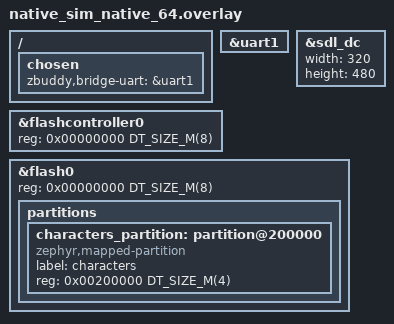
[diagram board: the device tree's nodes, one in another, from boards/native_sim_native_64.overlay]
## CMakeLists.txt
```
# Copyright (c) 2026 Muhammad Waleed Badar
# SPDX-License-Identifier: GPL-3.0-only

cmake_minimum_required(VERSION 3.20.0)

find_package(Zephyr REQUIRED HINTS $ENV{ZEPHYR_BASE})
project(zbuddy_app LANGUAGES C)

target_sources(app PRIVATE
  src/main.c
  src/buddy.c
  src/clock.c
  src/ui.c
  src/art_canvas.c
  src/character.c
  src/storage.c
  src/persist.c
  src/bridge.c
  src/hw.c
)

# The built-in character (tools/mkpack.py), shown until a pack is pushed
target_sources_ifdef(CONFIG_ZBUDDY_APP_BUILTIN_CHARACTER app PRIVATE src/builtin_pack.c)

# Transports: BLE (the desktop app) and a UART (tools/bridge_sim.py, tests)
target_sources_ifdef(CONFIG_BT app PRIVATE src/bridge_ble.c)
target_sources_ifdef(CONFIG_ZBUDDY_APP_UART_BRIDGE app PRIVATE src/bridge_uart.c)
# native_sim: command line options (screenshots, scripted bridge traffic)
target_sources_ifdef(CONFIG_BOARD_NATIVE_SIM app PRIVATE src/host.c)
```

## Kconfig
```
# Copyright (c) 2026 Muhammad Waleed Badar
# SPDX-License-Identifier: GPL-3.0-only

mainmenu "zbuddy"

DT_CHOSEN_BRIDGE_UART := zbuddy,bridge-uart

config ZBUDDY_APP_UART_BRIDGE
	bool "Speak the protocol over a UART as well (chosen zbuddy,bridge-uart)"
	default y if $(dt_chosen_enabled,$(DT_CHOSEN_BRIDGE_UART))
	depends on $(dt_chosen_enabled,$(DT_CHOSEN_BRIDGE_UART))
	select SERIAL
	select UART_INTERRUPT_DRIVEN
	help
	  The desktop app only talks BLE, but the same newline-delimited JSON
	  on a UART lets tools/bridge_sim.py drive the device, and is the
	  bridge of the native_sim build.

config ZBUDDY_APP_BUILTIN_CHARACTER
	bool "Built-in character pack (the clawd crab) until one is pushed"
	default y
	help
	  app/src/builtin_pack.c, generated by tools/mkpack.py from
	  characters/clawd. A pack pushed from the desktop replaces it; the
	  "delete char" reset brings it back.

config ZBUDDY_APP_BRIDGE_DEBUG
	bool "Log every write and notification of the bridge"
	help
	  Shows what the desktop sends and what the device answers, byte
	  counts and the first bytes of each line. Chatty during a pack push.

config ZBUDDY_APP_MOUNT_POINT
	string "Mount point of the character storage"
	default "/lfs"

config ZBUDDY_APP_SCREEN_OFF_S
	int "Turn the screen off after this many idle seconds (0 = never)"
	default 0
	help
	  The original device runs on a battery and sleeps after 30 s; a USB
	  powered board keeps the pet (and the clock) visible.

config ZBUDDY_APP_TICK_MS
	int "Animation tick of the ASCII pets (ms)"
	default 200

config ZBUDDY_APP_BLE_PREFIX
	string "Advertised name prefix (the desktop looks for Claude*)"
	default "Claude"

config ZBUDDY_APP_LED
	bool "Blink the RGB LED while an approval is pending"
	default y
	depends on LED_STRIP

config ZBUDDY_APP_SOUND
	bool "Beep on prompts and buttons (buzzer0 alias)"
	default y
	depends on BUZZER

source "Kconfig.zephyr"
```

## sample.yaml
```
# Copyright (c) 2026 Muhammad Waleed Badar
# SPDX-License-Identifier: GPL-3.0-only

sample:
  name: zbuddy
tests:
  app.zbuddy:
    build_only: true
    platform_allow:
      - native_sim/native/64
      - uedx32480035e_wb_a/esp32s3/procpu
    integration_platforms:
      - native_sim/native/64
    tags:
      - zbuddy
```

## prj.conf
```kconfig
# Copyright (c) 2026 Muhammad Waleed Badar
# SPDX-License-Identifier: GPL-3.0-only

# --- Buddy library -----------------------------------------------------------
CONFIG_ZBUDDY=y

# --- Kernel ------------------------------------------------------------------
# The main thread runs LVGL and the pet; it sleeps every iteration so that
# the Bluetooth, input, log and shell threads get the processor.
CONFIG_MAIN_THREAD_PRIORITY=12
CONFIG_MAIN_STACK_SIZE=16384
CONFIG_HEAP_MEM_POOL_SIZE=65536
CONFIG_LOG=y
CONFIG_LOG_DEFAULT_LEVEL=3
CONFIG_BASE64=y
CONFIG_REBOOT=y

# --- Character packs and settings on flash ----------------------------------
CONFIG_FLASH=y
CONFIG_FLASH_MAP=y
CONFIG_FILE_SYSTEM=y
CONFIG_FILE_SYSTEM_LITTLEFS=y
CONFIG_NVS=y
CONFIG_SETTINGS=y
CONFIG_SETTINGS_NVS=y

# --- Display and touch (LVGL) -------------------------------------------------
CONFIG_DISPLAY=y
CONFIG_INPUT=y
CONFIG_INPUT_QUEUE_MAX_MSGS=64
# The input thread runs the LVGL pointer callback, which logs when LVGL's
# queue is full; the default 1024 bytes overflowed on the ESP32-S3
CONFIG_INPUT_THREAD_STACK_SIZE=2048
CONFIG_LVGL=y
CONFIG_LV_Z_POINTER_INPUT=y
CONFIG_LV_Z_POINTER_INPUT_MSGQ_COUNT=64
CONFIG_LV_Z_MEM_POOL_SIZE=131072
CONFIG_LV_THEME_DEFAULT_DARK=y
CONFIG_LV_USE_LABEL=y
CONFIG_LV_USE_BUTTON=y
CONFIG_LV_USE_BAR=y
CONFIG_LV_USE_FLEX=y
CONFIG_LV_USE_CANVAS=y
CONFIG_LV_USE_GIF=y
CONFIG_LV_FONT_MONTSERRAT_12=y
CONFIG_LV_FONT_MONTSERRAT_14=y
CONFIG_LV_FONT_MONTSERRAT_16=y
CONFIG_LV_FONT_MONTSERRAT_20=y
CONFIG_LV_FONT_MONTSERRAT_28=y
CONFIG_LV_FONT_MONTSERRAT_48=y
CONFIG_LV_FONT_UNSCII_8=y
CONFIG_LV_FONT_UNSCII_16=y
CONFIG_LV_FONT_DEFAULT_MONTSERRAT_14=y
```

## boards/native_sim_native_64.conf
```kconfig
# Copyright (c) 2026 Muhammad Waleed Badar
# SPDX-License-Identifier: GPL-3.0-only
#
# native_sim/native/64: the SDL window stands in for the display, the mouse
# for the touch screen, a pseudo terminal (uart1) for the BLE link and the
# flash simulator (--flash=<file>) for the character storage and settings.

CONFIG_LV_COLOR_DEPTH_32=y
# The native backend prints the logs; the UART one would print them twice
CONFIG_LOG_BACKEND_UART=n

# Room for lv_snapshot_take() of the whole screen (--shot) and the GIFs
CONFIG_LV_USE_SNAPSHOT=y
CONFIG_LV_Z_MEM_POOL_SIZE=4194304

# Character packs are read into the kernel heap
CONFIG_HEAP_MEM_POOL_SIZE=16777216

# The console (logs) on the terminal; the bridge is uart1 on its own pty
CONFIG_UART_NATIVE_PTY_0_ON_STDINOUT=y
```

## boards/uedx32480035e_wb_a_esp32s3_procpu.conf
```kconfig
# Copyright (c) 2026 Muhammad Waleed Badar
# SPDX-License-Identifier: GPL-3.0-only
#
# VIEWE UEDX32480035E-WB-A (ESP32-S3): the BLE link to Claude Desktop, the
# character packs on the 16 MB flash, LVGL's pool and the GIFs in PSRAM.

CONFIG_ESP_SPIRAM=y
CONFIG_LV_Z_MEMORY_POOL_CUSTOM_SECTION=y
CONFIG_LV_Z_MEM_POOL_SIZE=524288
CONFIG_INPUT_THREAD_PRIORITY_OVERRIDE=y
CONFIG_INPUT_THREAD_PRIORITY=5
# Render the next strip while the previous one goes out over SPI
CONFIG_LV_Z_FLUSH_THREAD=y
CONFIG_LV_Z_DOUBLE_VDB=y

# --- Bluetooth LE: peripheral with the Nordic UART Service, LE Secure
# Connections with a passkey shown on the display, bonds in the settings
CONFIG_BT=y
CONFIG_BT_PERIPHERAL=y
CONFIG_BT_DEVICE_NAME="Claude"
CONFIG_BT_DEVICE_NAME_DYNAMIC=y
CONFIG_BT_SMP=y
CONFIG_BT_SMP_SC_PAIR_ONLY=y
CONFIG_BT_SETTINGS=y
CONFIG_BT_MAX_PAIRED=4
CONFIG_BT_L2CAP_TX_MTU=247
CONFIG_BT_BUF_ACL_RX_SIZE=251
CONFIG_BT_BUF_ACL_TX_SIZE=251
CONFIG_BT_GATT_CLIENT=n
# Show the desktop's traffic on the console while the link is being brought up
CONFIG_ZBUDDY_APP_BRIDGE_DEBUG=y

# --- The RGB LED blinks on a pending approval, the buzzer chirps
CONFIG_LED_STRIP=y
CONFIG_SPI=y
CONFIG_BUZZER=y
```

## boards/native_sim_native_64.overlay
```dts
/*
 * Copyright (c) 2026 Muhammad Waleed Badar
 * SPDX-License-Identifier: GPL-3.0-only
 *
 * The display has the geometry of the VIEWE board, upright like the device.
 * uart1 is the bridge: the simulator prints the pseudo terminal it is on,
 * tools/bridge_sim.py connects to it. The simulated flash grows to 8 MB to
 * hold a character pack next to the settings.
 */
/ {
	chosen {
		zbuddy,bridge-uart = &uart1;
	};
};

&uart1 {
	status = "okay";
};

&sdl_dc {
	width = <320>;
	height = <480>;
};

&flashcontroller0 {
	reg = <0x00000000 DT_SIZE_M(8)>;
};

&flash0 {
	reg = <0x00000000 DT_SIZE_M(8)>;
	ranges = <0x0 0x0 DT_SIZE_M(8)>;

	partitions {
		characters_partition: partition@200000 {
			compatible = "zephyr,mapped-partition";
			label = "characters";
			reg = <0x00200000 DT_SIZE_M(4)>;
		};
	};
};
```

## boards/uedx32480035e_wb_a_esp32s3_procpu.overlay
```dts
/*
 * Copyright (c) 2026 Muhammad Waleed Badar
 * SPDX-License-Identifier: GPL-3.0-only
 *
 * VIEWE UEDX32480035E-WB-A upright (320x480), the board's own orientation.
 * uart0 (the header pins) also speaks the protocol for tools/bridge_sim.py;
 * the console stays on the USB serial port.
 *
 * Flash: the application does not use MCUboot or the second core, so the
 * second image slots make room for a 4 MB character partition. The 192 KB
 * storage partition keeps the settings and the Bluetooth bonds.
 */
/ {
	chosen {
		zbuddy,bridge-uart = &uart0;
	};

	aliases {
		zbuddy-backlight = &{/lcd_backlight_en};
	};
};

/delete-node/ &slot1_partition;
/delete-node/ &slot0_appcpu_partition;
/delete-node/ &slot1_appcpu_partition;
/delete-node/ &slot0_lpcore_partition;
/delete-node/ &slot1_lpcore_partition;

&flash0 {
	partitions {
		characters_partition: partition@5f0000 {
			compatible = "zephyr,mapped-partition";
			label = "characters";
			reg = <0x5f0000 DT_SIZE_M(4)>;
		};
	};
};

/* GPIO0 is both the BOOT button and the RGB LED's data line (SPI3 MOSI).
 * Once the LED driver owns the pin it reads low, which the button driver
 * took for a press: a long press at boot opened the menu, and LED blinks
 * during a prompt could approve it. The LED wins; touch does the rest.
 */
&keys {
	status = "disabled";
};

/* Only the panel's gamma curves are set here */
&st7796s {
	pgc = [f0 06 0b 07 06 05 2e 33 47 3a 17 16 2e 31];
	ngc = [f0 09 0d 09 08 23 2e 33 46 38 13 13 2c 32];
};
```

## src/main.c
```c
/*
 * Copyright (c) 2026 Muhammad Waleed Badar
 * SPDX-License-Identifier: GPL-3.0-only
 *
 * zbuddy: a desk pet for Claude Desktop on Zephyr. It sleeps when nothing
 * is happening, wakes when sessions start, gets impatient when an approval
 * is pending, and lets you approve or deny from the device.
 */
#include "bridge.h"
#include "buddy.h"
#include "host.h"
#include "hw.h"
#include "persist.h"
#include "storage.h"
#include "ui.h"

#include <zbuddy/stats.h>
#include <zephyr/device.h>
#include <zephyr/drivers/display.h>
#include <zephyr/kernel.h>
#include <zephyr/logging/log.h>
#include <lvgl.h>

LOG_MODULE_REGISTER(zbuddy_app, LOG_LEVEL_INF);

int main(void)
{
	const struct device *display = DEVICE_DT_GET(DT_CHOSEN(zephyr_display));
	struct persist_data *d;
	uint32_t now = k_uptime_get_32();

	if (!device_is_ready(display)) {
		LOG_ERR("display not ready");
		return 0;
	}
	hw_init();
	persist_init();
	d = persist_get();
	zbuddy_stats_init(d->have_stats ? &d->stats : NULL, persist_save_stats, now);
	if (storage_init() != 0) {
		LOG_WRN("character storage unavailable");
	}
	ui_init();
	buddy_init(now);
	bridge_init();
	host_init();
	display_blanking_off(display);
	LOG_INF("zbuddy ready");

	for (;;) {
		struct hw_events ev;
		uint32_t next;

		now = k_uptime_get_32();
		bridge_poll(buddy_proto(), now);
		buddy_tick(now);
		hw_poll(now, &ev);
		if (ev.button_long) {
			buddy_long_press(now);
		} else if (ev.button_short) {
			buddy_button_short(now);
		}
		ui_update(now);
		host_poll(now);
		next = lv_timer_handler();
		/* at least a few ms: the lower-priority log and shell threads need it */
		k_msleep(CLAMP(next, 5, 20));
	}
	return 0;
}
```

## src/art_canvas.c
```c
/*
 * Copyright (c) 2026 Muhammad Waleed Badar
 * SPDX-License-Identifier: GPL-3.0-only
 */
#include "art_canvas.h"

#include <string.h>

LV_DRAW_BUF_DEFINE_STATIC(art_buf, ZBUDDY_ART_CANVAS_W, ZBUDDY_ART_CANVAS_H,
			  LV_COLOR_FORMAT_RGB565);

static lv_obj_t *canvas;
static lv_layer_t layer;
static lv_color_t cur_color;
static int cur_x, cur_y;

lv_color_t art_color_from_565(uint16_t c)
{
	uint8_t r = (uint8_t)(((c >> 11) & 0x1F) << 3);
	uint8_t g = (uint8_t)(((c >> 5) & 0x3F) << 2);
	uint8_t b = (uint8_t)((c & 0x1F) << 3);

	return lv_color_make((uint8_t)(r | (r >> 5)), (uint8_t)(g | (g >> 6)), (uint8_t)(b | (b >> 5)));
}

static void op_color(uint16_t rgb565)
{
	cur_color = art_color_from_565(rgb565);
}

static void op_cursor(int x, int y)
{
	cur_x = x;
	cur_y = y;
}

static void op_print(const char *s)
{
	lv_draw_label_dsc_t dsc;
	lv_area_t area;
	int len = (int)strlen(s);

	if (len == 0) {
		return;
	}
	lv_draw_label_dsc_init(&dsc);
	dsc.font = &lv_font_unscii_8;
	dsc.color = cur_color;
	dsc.text = s;
	dsc.text_local = 1;
	area.x1 = cur_x;
	area.y1 = cur_y;
	area.x2 = cur_x + len * ZBUDDY_ART_CHAR_W - 1;
	area.y2 = cur_y + ZBUDDY_ART_CHAR_H - 1;
	lv_draw_label(&layer, &dsc, &area);
	cur_x += len * ZBUDDY_ART_CHAR_W;
}

static const struct zbuddy_art_ops ops = {
	.set_color = op_color,
	.set_cursor = op_cursor,
	.print = op_print,
};

lv_obj_t *art_canvas_create(lv_obj_t *parent, int32_t scale)
{
	LV_DRAW_BUF_INIT_STATIC(art_buf);
	canvas = lv_canvas_create(parent);
	lv_canvas_set_draw_buf(canvas, &art_buf);
	lv_image_set_pivot(canvas, 0, 0);
	lv_image_set_scale(canvas, (uint32_t)LV_MAX(1, scale) * LV_SCALE_NONE);
	lv_image_set_antialias(canvas, false);
	lv_canvas_fill_bg(canvas, lv_color_black(), LV_OPA_COVER);
	zbuddy_art_bind(&ops);
	return canvas;
}

void art_canvas_render(const struct zbuddy_species *sp, enum zbuddy_persona s, uint32_t t,
		       uint16_t bg565)
{
	if (canvas == NULL) {
		return;
	}
	lv_canvas_fill_bg(canvas, art_color_from_565(bg565), LV_OPA_COVER);
	lv_canvas_init_layer(canvas, &layer);
	zbuddy_art_render(sp, s, t);
	lv_canvas_finish_layer(canvas, &layer);
	lv_obj_invalidate(canvas);
}
```

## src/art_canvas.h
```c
/*
 * Copyright (c) 2026 Muhammad Waleed Badar
 * SPDX-License-Identifier: GPL-3.0-only
 *
 * The text canvas of the ASCII species as an LVGL canvas: 160x88 at 1x,
 * shown at a whole pixel scale with nearest-neighbour scaling for the
 * pixel look.
 */
#ifndef ZBUDDY_APP_ART_CANVAS_H
#define ZBUDDY_APP_ART_CANVAS_H

#include <zbuddy/art.h>
#include <lvgl.h>

/** @p scale is the whole pixel scale the canvas is shown at. */
lv_obj_t *art_canvas_create(lv_obj_t *parent, int32_t scale);
/** Draw one frame; @p bg565 is the background colour. */
void art_canvas_render(const struct zbuddy_species *sp, enum zbuddy_persona s, uint32_t t,
		       uint16_t bg565);
lv_color_t art_color_from_565(uint16_t c);

#endif
```

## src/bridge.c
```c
/*
 * Copyright (c) 2026 Muhammad Waleed Badar
 * SPDX-License-Identifier: GPL-3.0-only
 */
#include "bridge.h"

#include <zephyr/kernel.h>
#include <zephyr/logging/log.h>
#include <zephyr/sys/ring_buffer.h>

#if defined(CONFIG_ZBUDDY_APP_BRIDGE_DEBUG)
LOG_MODULE_REGISTER(bridge, LOG_LEVEL_DBG);
#else
LOG_MODULE_REGISTER(bridge, LOG_LEVEL_INF);
#endif

RING_BUF_DECLARE(rx_ring, 8192);
static struct k_spinlock rx_lock;

void bridge_rx_put(const uint8_t *data, size_t len)
{
	k_spinlock_key_t key = k_spin_lock(&rx_lock);
	uint32_t n = ring_buf_put(&rx_ring, data, (uint32_t)len);

	k_spin_unlock(&rx_lock, key);
	if (n < len) {
		LOG_WRN("rx ring full, %u bytes dropped", (unsigned int)(len - n));
	}
}

void bridge_poll(struct zbuddy_proto *p, uint32_t now_ms)
{
	uint8_t buf[256];

#if defined(CONFIG_BT)
	bridge_ble_poll(now_ms);
#endif
	for (;;) {
		k_spinlock_key_t key = k_spin_lock(&rx_lock);
		uint32_t n = ring_buf_get(&rx_ring, buf, sizeof(buf));

		k_spin_unlock(&rx_lock, key);
		if (n == 0) {
			return;
		}
		LOG_DBG("feeding %u bytes", n);
		zbuddy_proto_feed(p, buf, n, now_ms);
	}
}

void bridge_send(const char *line, size_t len)
{
#if defined(CONFIG_BT)
	bridge_ble_send(line, len);
#endif
#if defined(CONFIG_ZBUDDY_APP_UART_BRIDGE)
	bridge_uart_send(line, len);
#endif
}

void bridge_init(void)
{
#if defined(CONFIG_ZBUDDY_APP_UART_BRIDGE)
	if (bridge_uart_init() != 0) {
		LOG_WRN("uart bridge unavailable");
	}
#endif
#if defined(CONFIG_BT)
	if (bridge_ble_init() != 0) {
		LOG_WRN("bluetooth unavailable");
	}
#endif
}

static uint32_t debug_passkey;

void bridge_debug_passkey(uint32_t passkey)
{
	debug_passkey = passkey;
}

uint32_t bridge_debug_passkey_get(void)
{
	return debug_passkey;
}

#if !defined(CONFIG_BT)
bool bridge_ble_available(void)
{
	return false;
}
bool bridge_ble_connected(void)
{
	return false;
}
bool bridge_ble_secure(void)
{
	return false;
}
uint32_t bridge_ble_passkey(void)
{
	return debug_passkey;
}
const char *bridge_ble_name(void)
{
	return "(no bluetooth)";
}
const char *bridge_ble_addr(void)
{
	return "-";
}
void bridge_ble_unpair(void)
{
}
#endif
```

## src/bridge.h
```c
/*
 * Copyright (c) 2026 Muhammad Waleed Badar
 * SPDX-License-Identifier: GPL-3.0-only
 *
 * The bridge: bytes between the desktop and the protocol parser, over BLE
 * (Nordic UART Service) and optionally a UART. Both transports push into
 * one receive ring; the main loop drains it into the parser. Lines sent by
 * the parser go to every transport that is up.
 */
#ifndef ZBUDDY_APP_BRIDGE_H
#define ZBUDDY_APP_BRIDGE_H

#include <zbuddy/proto.h>

void bridge_init(void);
/** Drain received bytes into the parser. */
void bridge_poll(struct zbuddy_proto *p, uint32_t now_ms);
/** Send one line to all transports. */
void bridge_send(const char *line, size_t len);
/** Transports call this from any context. */
void bridge_rx_put(const uint8_t *data, size_t len);

/* Bluetooth facts for the screens; stubs without CONFIG_BT */
bool bridge_ble_available(void);
bool bridge_ble_connected(void);
bool bridge_ble_secure(void);
/** Non-zero while a passkey must be shown to the user. */
uint32_t bridge_ble_passkey(void);
const char *bridge_ble_name(void);
const char *bridge_ble_addr(void);
void bridge_ble_unpair(void);

/* Implemented by the transports */
int bridge_ble_init(void);
void bridge_ble_send(const char *line, size_t len);
/** Keeps advertising alive while disconnected; call every loop. */
void bridge_ble_poll(uint32_t now_ms);
int bridge_uart_init(void);
void bridge_uart_send(const char *line, size_t len);

/** Debug: pretend a passkey is being shown (screenshots). */
void bridge_debug_passkey(uint32_t passkey);
uint32_t bridge_debug_passkey_get(void);

#endif
```

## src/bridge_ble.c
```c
/*
 * Copyright (c) 2026 Muhammad Waleed Badar
 * SPDX-License-Identifier: GPL-3.0-only
 *
 * BLE peripheral for Claude Desktop: the Nordic UART Service UUIDs with
 * encrypted-only characteristics, LE Secure Connections bonding with the
 * passkey shown on the display (DisplayOnly), advertised as "Claude-XXXX".
 */
#include "bridge.h"

#include <stdio.h>
#include <string.h>
#include <zephyr/bluetooth/bluetooth.h>
#include <zephyr/bluetooth/conn.h>
#include <zephyr/bluetooth/gatt.h>
#include <zephyr/bluetooth/hci.h>
#include <zephyr/bluetooth/uuid.h>
#include <zephyr/kernel.h>
#include <zephyr/logging/log.h>
#include <zephyr/settings/settings.h>

#if defined(CONFIG_ZBUDDY_APP_BRIDGE_DEBUG)
LOG_MODULE_REGISTER(bridge_ble, LOG_LEVEL_DBG);
#else
LOG_MODULE_REGISTER(bridge_ble, LOG_LEVEL_INF);
#endif

#define NUS_SRV_VAL BT_UUID_128_ENCODE(0x6e400001, 0xb5a3, 0xf393, 0xe0a9, 0xe50e24dcca9e)
#define NUS_RX_VAL BT_UUID_128_ENCODE(0x6e400002, 0xb5a3, 0xf393, 0xe0a9, 0xe50e24dcca9e)
#define NUS_TX_VAL BT_UUID_128_ENCODE(0x6e400003, 0xb5a3, 0xf393, 0xe0a9, 0xe50e24dcca9e)

static struct bt_conn *current;
static bool notify_enabled;
static bool secure;
static uint32_t passkey;
static char dev_name[24] = CONFIG_ZBUDDY_APP_BLE_PREFIX;
static char dev_addr[BT_ADDR_LE_STR_LEN] = "-";

static ssize_t rx_write(struct bt_conn *conn, const struct bt_gatt_attr *attr, const void *buf,
			uint16_t len, uint16_t offset, uint8_t flags)
{
	ARG_UNUSED(conn);
	ARG_UNUSED(attr);
	ARG_UNUSED(offset);
	ARG_UNUSED(flags);
	LOG_DBG("rx %u bytes: %.*s", len, (int)MIN(len, 60), (const char *)buf);
	bridge_rx_put(buf, len);
	return len;
}

static void tx_ccc_changed(const struct bt_gatt_attr *attr, uint16_t value)
{
	ARG_UNUSED(attr);
	notify_enabled = (value == BT_GATT_CCC_NOTIFY);
	LOG_INF("notifications %s", notify_enabled ? "on" : "off");
}

BT_GATT_SERVICE_DEFINE(nus_svc, BT_GATT_PRIMARY_SERVICE(BT_UUID_DECLARE_128(NUS_SRV_VAL)),
		       BT_GATT_CHARACTERISTIC(BT_UUID_DECLARE_128(NUS_TX_VAL), BT_GATT_CHRC_NOTIFY,
					      BT_GATT_PERM_READ_ENCRYPT, NULL, NULL, NULL),
		       BT_GATT_CCC(tx_ccc_changed,
				   BT_GATT_PERM_READ_ENCRYPT | BT_GATT_PERM_WRITE_ENCRYPT),
		       BT_GATT_CHARACTERISTIC(BT_UUID_DECLARE_128(NUS_RX_VAL),
					      BT_GATT_CHRC_WRITE | BT_GATT_CHRC_WRITE_WITHOUT_RESP,
					      BT_GATT_PERM_WRITE_ENCRYPT, NULL, rx_write, NULL), );

#define TX_ATTR (&nus_svc.attrs[2])

static const struct bt_data ad[] = {
	BT_DATA_BYTES(BT_DATA_FLAGS, (BT_LE_AD_GENERAL | BT_LE_AD_NO_BREDR)),
	BT_DATA(BT_DATA_NAME_COMPLETE, dev_name, 0), /* length patched at start */
};

static const struct bt_data sd[] = {
	BT_DATA_BYTES(BT_DATA_UUID128_ALL, NUS_SRV_VAL),
};

static bool advertising;

static void start_adv(void)
{
	struct bt_data ad_now[2] = {ad[0], ad[1]};
	int err;

	ad_now[1].data_len = (uint8_t)strlen(dev_name);
	err = bt_le_adv_start(BT_LE_ADV_CONN_FAST_1, ad_now, ARRAY_SIZE(ad_now), sd, ARRAY_SIZE(sd));
	if (err == -EALREADY) {
		advertising = true;
	} else if (err != 0) {
		advertising = false;
		LOG_ERR("advertising failed (%d)", err);
	} else {
		advertising = true;
		LOG_INF("advertising as '%s'", dev_name);
	}
}

/* Advertising must be running whenever nobody is connected: a failed
 * pairing followed by a disconnect from both sides can leave it stopped,
 * so the main loop checks it every few seconds.
 */
void bridge_ble_poll(uint32_t now_ms)
{
	static uint32_t next_check;

	if ((int32_t)(now_ms - next_check) < 0) {
		return;
	}
	next_check = now_ms + 5000;
	if (current == NULL && !advertising) {
		LOG_WRN("advertising stopped, restarting");
		start_adv();
	}
}

static void connected(struct bt_conn *conn, uint8_t err)
{
	advertising = false; /* a connectable advertiser stops on connection */
	if (err != 0) {
		LOG_WRN("connection failed (%u)", err);
		start_adv();
		return;
	}
	current = bt_conn_ref(conn);
	secure = false;
	passkey = 0;
	{
		char addr[BT_ADDR_LE_STR_LEN];

		bt_addr_le_to_str(bt_conn_get_dst(conn), addr, sizeof(addr));
		LOG_INF("connected to %s", addr);
	}
}

static void disconnected(struct bt_conn *conn, uint8_t reason)
{
	LOG_INF("disconnected (%u)", reason);
	if (current == conn) {
		bt_conn_unref(current);
		current = NULL;
	}
	notify_enabled = false;
	secure = false;
	passkey = 0;
}

static void recycled(void)
{
	start_adv();
}

static void security_changed(struct bt_conn *conn, bt_security_t level, enum bt_security_err err)
{
	ARG_UNUSED(conn);
	secure = (err == BT_SECURITY_ERR_SUCCESS && level >= BT_SECURITY_L2);
	LOG_INF("security level %d (%d), mtu %u", level, err, bt_gatt_get_mtu(conn));
}

static void le_param_updated(struct bt_conn *conn, uint16_t interval, uint16_t latency,
			     uint16_t timeout)
{
	ARG_UNUSED(conn);
	LOG_INF("conn params: interval %u.%02u ms, latency %u, timeout %u ms", interval * 125 / 100,
		(interval * 125) % 100, latency, timeout * 10);
}

BT_CONN_CB_DEFINE(conn_cbs) = {
	.connected = connected,
	.disconnected = disconnected,
	.recycled = recycled,
	.security_changed = security_changed,
	.le_param_updated = le_param_updated,
};

static void passkey_display(struct bt_conn *conn, unsigned int key)
{
	ARG_UNUSED(conn);
	passkey = key;
	LOG_INF("passkey %06u", key);
}

static void auth_cancel(struct bt_conn *conn)
{
	ARG_UNUSED(conn);
	passkey = 0;
	LOG_INF("pairing cancelled");
}

static const struct bt_conn_auth_cb auth_cb = {
	.passkey_display = passkey_display,
	.cancel = auth_cancel,
};

static void pairing_complete(struct bt_conn *conn, bool bonded)
{
	ARG_UNUSED(conn);
	passkey = 0;
	LOG_INF("pairing complete, %s", bonded ? "bonded" : "not bonded");
}

static void pairing_failed(struct bt_conn *conn, enum bt_security_err reason)
{
	passkey = 0;
	LOG_WRN("pairing failed (%d): %s", reason,
		reason == BT_SECURITY_ERR_AUTH_REQUIREMENT
			? "the host offers no passkey entry (pair it with an agent)"
		: reason == BT_SECURITY_ERR_PIN_OR_KEY_MISSING
			? "stale bond on the host, pair again"
			: "");
	bt_conn_disconnect(conn, BT_HCI_ERR_AUTH_FAIL);
}

static struct bt_conn_auth_info_cb auth_info_cb = {
	.pairing_complete = pairing_complete,
	.pairing_failed = pairing_failed,
};

int bridge_ble_init(void)
{
	bt_addr_le_t addrs[CONFIG_BT_ID_MAX];
	size_t count = ARRAY_SIZE(addrs);
	int err;

	err = bt_enable(NULL);
	if (err != 0) {
		LOG_ERR("bt_enable failed (%d)", err);
		return err;
	}
	if (IS_ENABLED(CONFIG_BT_SETTINGS)) {
		settings_load_subtree("bt");
	}
	bt_conn_auth_cb_register(&auth_cb);
	bt_conn_auth_info_cb_register(&auth_info_cb);

	/* "Claude-XXXX" with the last two bytes of the address, so several
	 * buddies in one room are distinguishable in the desktop picker.
	 */
	bt_id_get(addrs, &count);
	if (count > 0) {
		snprintf(dev_name, sizeof(dev_name), "%s-%02X%02X", CONFIG_ZBUDDY_APP_BLE_PREFIX,
			 addrs[0].a.val[1], addrs[0].a.val[0]);
		bt_addr_le_to_str(&addrs[0], dev_addr, sizeof(dev_addr));
		dev_addr[17] = '\0'; /* drop the " (public)" suffix */
	}
	bt_set_name(dev_name);
	start_adv();
	return 0;
}

void bridge_ble_send(const char *line, size_t len)
{
	size_t sent = 0;

	if (current == NULL || !notify_enabled) {
		return;
	}
	while (sent < len) {
		uint16_t mtu = bt_gatt_get_mtu(current);
		size_t chunk = mtu > 3 ? mtu - 3 : 20;
		size_t n = len - sent;
		int err;

		if (chunk > 244) {
			chunk = 244;
		}
		if (n > chunk) {
			n = chunk;
		}
		LOG_DBG("tx %u bytes: %.*s", (unsigned int)n, (int)MIN(n, 60), line + sent);
		err = bt_gatt_notify(current, TX_ATTR, line + sent, (uint16_t)n);
		if (err == -ENOMEM || err == -EAGAIN) {
			k_msleep(4);
			continue;
		}
		if (err != 0) {
			LOG_WRN("notify failed (%d)", err);
			return;
		}
		sent += n;
	}
}

bool bridge_ble_available(void)
{
	return true;
}

bool bridge_ble_connected(void)
{
	return current != NULL;
}

bool bridge_ble_secure(void)
{
	return secure;
}

uint32_t bridge_ble_passkey(void)
{
	return passkey != 0 ? passkey : bridge_debug_passkey_get();
}

const char *bridge_ble_name(void)
{
	return dev_name;
}

const char *bridge_ble_addr(void)
{
	return dev_addr;
}

void bridge_ble_unpair(void)
{
	int err = bt_unpair(BT_ID_DEFAULT, BT_ADDR_LE_ANY);

	LOG_INF("bonds cleared (%d)", err);
}
```

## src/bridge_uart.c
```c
/*
 * Copyright (c) 2026 Muhammad Waleed Badar
 * SPDX-License-Identifier: GPL-3.0-only
 *
 * The protocol over the chosen zbuddy,bridge-uart: interrupt driven
 * receive into the bridge ring, polled transmit (lines are short).
 */
#include "bridge.h"

#include <zephyr/device.h>
#include <zephyr/drivers/uart.h>
#include <zephyr/kernel.h>
#include <zephyr/logging/log.h>

LOG_MODULE_REGISTER(bridge_uart, LOG_LEVEL_INF);

static const struct device *const uart = DEVICE_DT_GET(DT_CHOSEN(zbuddy_bridge_uart));
static bool ready;

static void uart_isr(const struct device *dev, void *user_data)
{
	uint8_t buf[64];

	ARG_UNUSED(user_data);
	uart_irq_update(dev);
	while (uart_irq_rx_ready(dev)) {
		int n = uart_fifo_read(dev, buf, sizeof(buf));

		if (n <= 0) {
			break;
		}
		bridge_rx_put(buf, (size_t)n);
	}
}

int bridge_uart_init(void)
{
	if (!device_is_ready(uart)) {
		return -ENODEV;
	}
	uart_irq_callback_user_data_set(uart, uart_isr, NULL);
	uart_irq_rx_enable(uart);
	ready = true;
	LOG_INF("bridge on %s", uart->name);
	return 0;
}

void bridge_uart_send(const char *line, size_t len)
{
	if (!ready) {
		return;
	}
	for (size_t i = 0; i < len; i++) {
		uart_poll_out(uart, (unsigned char)line[i]);
	}
}
```

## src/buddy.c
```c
/*
 * Copyright (c) 2026 Muhammad Waleed Badar
 * SPDX-License-Identifier: GPL-3.0-only
 */
#include "buddy.h"
#include "bridge.h"
#include "character.h"
#include "clock.h"
#include "hw.h"
#include "storage.h"

#include <stdio.h>
#include <string.h>
#include <zbuddy/art.h>
#include <zbuddy/stats.h>
#include <zephyr/kernel.h>
#include <zephyr/logging/log.h>
#include <zephyr/sys/reboot.h>

LOG_MODULE_REGISTER(buddy, LOG_LEVEL_INF);

#define SPECIES_GIF 0xFF
#define WAKE_TRANSITION_MS 12000
#define RESET_CONFIRM_MS 3000

static struct buddy_model m;
static struct zbuddy_proto proto;
static char last_prompt_id[sizeof(((struct zbuddy_prompt *)0)->id)];
static int forced_persona = -1;

static const char *const menu_items[] = {"settings", "nap", "help", "about", "demo", "close"};
static const char *const settings_items[] = {"sound", "led", "transcript", "ascii pet",
					     "reset", "back"};
static const char *const reset_items[] = {"delete char", "factory reset", "back"};

/* --- protocol callbacks ---------------------------------------------------- */

static void op_send(const char *line, size_t len)
{
	bridge_send(line, len);
}

static void op_set_name(const char *name)
{
	struct persist_data *d = persist_get();

	strncpy(d->name, name, sizeof(d->name) - 1);
	d->name[sizeof(d->name) - 1] = '\0';
	persist_save_name();
}

static const char *op_get_name(void)
{
	return persist_get()->name;
}

static void op_set_owner(const char *name)
{
	struct persist_data *d = persist_get();

	strncpy(d->owner, name, sizeof(d->owner) - 1);
	d->owner[sizeof(d->owner) - 1] = '\0';
	persist_save_owner();
}

static const char *op_get_owner(void)
{
	return persist_get()->owner;
}

static void op_time_sync(int64_t epoch_s, int32_t tz_offset_s)
{
	clock_sync(epoch_s, tz_offset_s, k_uptime_get_32());
}

static void op_sys_info(struct zbuddy_sys_info *info)
{
	info->uptime_s = k_uptime_get_32() / 1000U;
	storage_space(&info->fs_free, &info->fs_total);
}

static const struct zbuddy_proto_ops ops = {
	.send = op_send,
	.set_name = op_set_name,
	.get_name = op_get_name,
	.set_owner = op_set_owner,
	.get_owner = op_get_owner,
	.set_species = buddy_set_species,
	.unpair = bridge_ble_unpair,
	.time_sync = op_time_sync,
	.sys_info = op_sys_info,
	.secure = bridge_ble_secure,
	/* .store is set at init: the storage may be absent */
};

static struct zbuddy_proto_ops live_ops;

/* --- helpers ----------------------------------------------------------------- */

static void beep(uint32_t ms)
{
	if (persist_get()->prefs.sound) {
		hw_beep(ms);
	}
}

static void one_shot(enum zbuddy_persona s, uint32_t dur_ms, uint32_t now_ms)
{
	m.active = s;
	m.one_shot_until = now_ms + dur_ms;
	m.anim_gen++;
}

void buddy_wake(uint32_t now_ms)
{
	m.last_interact_ms = now_ms;
	if (m.napping) {
		m.napping = false;
		zbuddy_stats_on_nap_end((now_ms - m.nap_start_ms) / 1000U, now_ms);
	}
	if (m.screen_off) {
		m.screen_off = false;
		hw_screen(true);
		m.wake_transition_until = now_ms + WAKE_TRANSITION_MS;
		m.anim_gen++;
	}
}

static void close_overlays(void)
{
	m.overlay = OVERLAY_NONE;
	m.sel = 0;
	m.reset_armed = 0xFF;
}

static void next_pet(void)
{
	struct persist_data *d = persist_get();
	uint8_t n = (uint8_t)zbuddy_species_count();

	if (!m.ascii_mode) { /* pack -> first species */
		m.ascii_mode = true;
		m.species_idx = 0;
	} else if (m.species_idx + 1 >= n && m.gif_available) { /* last species -> pack */
		m.ascii_mode = false;
	} else {
		m.species_idx = (uint8_t)((m.species_idx + 1) % n);
	}
	d->species = m.ascii_mode ? m.species_idx : SPECIES_GIF;
	persist_save_species();
	m.anim_gen++;
}

void buddy_set_species(uint8_t idx)
{
	struct persist_data *d = persist_get();

	m.gif_available = character_loaded();
	d->species = idx;
	persist_save_species();
	m.ascii_mode = !(m.gif_available && idx == SPECIES_GIF);
	if (m.ascii_mode && idx < zbuddy_species_count()) {
		m.species_idx = idx;
	}
	m.anim_gen++;
}

const char *buddy_species_name(void)
{
	if (m.ascii_mode) {
		const struct zbuddy_species *sp = zbuddy_species_get(m.species_idx);

		return sp != NULL ? sp->name : "?";
	}
	return character_loaded() ? character_name() : "none";
}

/* --- menus ------------------------------------------------------------------- */

static void apply_setting(uint8_t idx, uint32_t now_ms)
{
	struct persist_data *d = persist_get();

	ARG_UNUSED(now_ms);
	switch (idx) {
	case 0:
		d->prefs.sound = !d->prefs.sound;
		break;
	case 1:
		d->prefs.led = !d->prefs.led;
		if (!d->prefs.led) {
			hw_led(false);
		}
		break;
	case 2:
		d->prefs.hud = !d->prefs.hud;
		break;
	case 3:
		next_pet();
		return;
	case 4:
		m.overlay = OVERLAY_RESET;
		m.sel = 0;
		m.reset_armed = 0xFF;
		return;
	default:
		close_overlays();
		return;
	}
	persist_save_prefs();
}

/* Tap-twice confirm: the first activation arms ("really?"), the second
 * within three seconds executes.
 */
static void apply_reset(uint8_t idx, uint32_t now_ms)
{
	bool armed = (m.reset_armed == idx) && (int32_t)(now_ms - m.reset_armed_until) < 0;

	if (idx == 2) {
		close_overlays();
		return;
	}
	if (!armed) {
		m.reset_armed = idx;
		m.reset_armed_until = now_ms + RESET_CONFIRM_MS;
		beep(60);
		return;
	}
	beep(200);
	if (idx == 0) {
		character_close();
		storage_wipe_characters();
		character_init(NULL); /* the built-in pack, when there is one */
		m.gif_available = character_loaded();
		m.ascii_mode = !m.gif_available;
		persist_get()->species = m.ascii_mode ? m.species_idx : SPECIES_GIF;
		persist_save_species();
		close_overlays();
		m.anim_gen++;
		return;
	}
	/* factory reset: names, stats, preferences, packs and bonds */
	character_close();
	storage_wipe_characters();
	persist_wipe();
	zbuddy_stats_reset(now_ms);
	bridge_ble_unpair();
	k_msleep(300);
	sys_reboot(SYS_REBOOT_COLD);
}

static void menu_confirm(uint8_t idx, uint32_t now_ms)
{
	switch (idx) {
	case 0:
		m.overlay = OVERLAY_SETTINGS;
		m.sel = 0;
		break;
	case 1: /* nap: the screen goes dark until the next touch */
		close_overlays();
		m.napping = true;
		m.nap_start_ms = now_ms;
		m.screen_off = true;
		hw_screen(false);
		break;
	case 2:
	case 3:
		close_overlays();
		m.screen = SCREEN_INFO;
		m.info_page = (idx == 2) ? INFO_PG_BUTTONS : INFO_PG_CREDITS;
		break;
	case 4:
		zbuddy_proto_set_demo(&proto, !zbuddy_proto_demo(&proto), now_ms);
		break;
	default:
		close_overlays();
		break;
	}
}

void buddy_pick(uint8_t idx, uint32_t now_ms)
{
	buddy_wake(now_ms);
	beep(30);
	m.sel = idx;
	switch (m.overlay) {
	case OVERLAY_MENU:
		menu_confirm(idx, now_ms);
		break;
	case OVERLAY_SETTINGS:
		apply_setting(idx, now_ms);
		break;
	case OVERLAY_RESET:
		apply_reset(idx, now_ms);
		break;
	default:
		break;
	}
}

const char *buddy_overlay_title(void)
{
	switch (m.overlay) {
	case OVERLAY_MENU:
		return "menu";
	case OVERLAY_SETTINGS:
		return "settings";
	case OVERLAY_RESET:
		return "reset";
	default:
		return "";
	}
}

uint8_t buddy_overlay_items(void)
{
	switch (m.overlay) {
	case OVERLAY_MENU:
		return ARRAY_SIZE(menu_items);
	case OVERLAY_SETTINGS:
		return ARRAY_SIZE(settings_items);
	case OVERLAY_RESET:
		return ARRAY_SIZE(reset_items);
	default:
		return 0;
	}
}

void buddy_overlay_item(uint8_t idx, char *buf, size_t len, uint32_t now_ms)
{
	const struct buddy_prefs *p = &persist_get()->prefs;

	switch (m.overlay) {
	case OVERLAY_MENU:
		if (idx == 4) {
			snprintf(buf, len, "%-12s%s", menu_items[idx],
				 zbuddy_proto_demo(&proto) ? "on" : "off");
		} else {
			snprintf(buf, len, "%s", menu_items[idx]);
		}
		break;
	case OVERLAY_SETTINGS:
		switch (idx) {
		case 0:
		case 1:
		case 2: {
			bool v = idx == 0 ? p->sound : idx == 1 ? p->led : p->hud;

			snprintf(buf, len, "%-12s%s", settings_items[idx], v ? "on" : "off");
			break;
		}
		case 3: {
			uint8_t total = (uint8_t)zbuddy_species_count() + (m.gif_available ? 1 : 0);
			uint8_t pos = m.ascii_mode ? m.species_idx + 1 : total;

			snprintf(buf, len, "%-12s%u/%u %s", settings_items[idx], pos, total,
				 buddy_species_name());
			break;
		}
		default:
			snprintf(buf, len, "%s", settings_items[idx]);
			break;
		}
		break;
	case OVERLAY_RESET: {
		bool armed = (m.reset_armed == idx) && (int32_t)(now_ms - m.reset_armed_until) < 0;

		snprintf(buf, len, "%s", armed ? "really?" : reset_items[idx]);
		break;
	}
	default:
		buf[0] = '\0';
		break;
	}
}

/* --- inputs ------------------------------------------------------------------ */

static void send_decision(bool approve, uint32_t now_ms)
{
	const struct zbuddy_snapshot *s = &proto.snap;

	if (!m.in_prompt) {
		return;
	}
	zbuddy_proto_permission(&proto, s->prompt.id, approve);
	LOG_INF("prompt %s: %s", s->prompt.id, approve ? "approved" : "denied");
	m.response_sent = true;
	m.in_prompt = false;
	if (approve) {
		uint32_t took_s = (now_ms - m.prompt_arrived_ms) / 1000U;

		zbuddy_stats_on_approval(took_s);
		beep(60);
		if (took_s < 5) {
			one_shot(ZBUDDY_HEART, 2000, now_ms);
		}
	} else {
		zbuddy_stats_on_denial();
		beep(60);
	}
}

void buddy_approve(uint32_t now_ms)
{
	buddy_wake(now_ms);
	send_decision(true, now_ms);
}

void buddy_deny(uint32_t now_ms)
{
	buddy_wake(now_ms);
	send_decision(false, now_ms);
}

void buddy_tap_pet(uint32_t now_ms)
{
	bool was_off = m.screen_off;

	buddy_wake(now_ms);
	if (was_off || m.overlay != OVERLAY_NONE) {
		return;
	}
	if (m.in_prompt) {
		send_decision(true, now_ms);
		return;
	}
	beep(30);
	m.screen = (enum buddy_screen)((m.screen + 1) % SCREEN_COUNT);
}

void buddy_next_page(uint32_t now_ms)
{
	bool was_off = m.screen_off;

	buddy_wake(now_ms);
	if (was_off || m.overlay != OVERLAY_NONE) {
		return;
	}
	beep(30);
	if (m.screen == SCREEN_INFO) {
		m.info_page = (uint8_t)((m.info_page + 1) % INFO_PAGES);
	} else if (m.screen == SCREEN_PET) {
		m.pet_page = (uint8_t)((m.pet_page + 1) % PET_PAGES);
	}
}

void buddy_long_press(uint32_t now_ms)
{
	bool was_off = m.screen_off;

	buddy_wake(now_ms);
	if (was_off) {
		return;
	}
	beep(60);
	if (m.overlay != OVERLAY_NONE) {
		buddy_pick(m.sel, now_ms);
		return;
	}
	m.overlay = OVERLAY_MENU;
	m.sel = 0;
}

void buddy_button_short(uint32_t now_ms)
{
	bool was_off = m.screen_off;

	buddy_wake(now_ms);
	if (was_off) {
		return;
	}
	if (m.overlay != OVERLAY_NONE) {
		beep(30);
		m.sel = (uint8_t)((m.sel + 1) % buddy_overlay_items());
		if (m.overlay == OVERLAY_RESET) {
			m.reset_armed = 0xFF;
		}
		return;
	}
	buddy_tap_pet(now_ms);
}

void buddy_shake(uint32_t now_ms)
{
	if (m.overlay != OVERLAY_NONE || m.screen_off) {
		return;
	}
	buddy_wake(now_ms);
	if ((int32_t)(now_ms - m.one_shot_until) >= 0) {
		one_shot(ZBUDDY_DIZZY, 2000, now_ms);
		LOG_INF("shake: dizzy");
	}
}

/* --- the loop ---------------------------------------------------------------- */

void buddy_init(uint32_t now_ms)
{
	struct persist_data *d = persist_get();

	live_ops = ops;
	live_ops.store = storage_ready() ? storage_store() : NULL;
	zbuddy_proto_init(&proto, &live_ops);
	memset(&m, 0, sizeof(m));
	m.reset_armed = 0xFF;
	m.last_interact_ms = now_ms;

	character_init(NULL);
	m.gif_available = character_loaded();
	/* 0..N-1 = ASCII species, 0xFF = the installed pack (the default, so
	 * a freshly pushed pack is what shows); without a pack, ASCII */
	m.ascii_mode = !(m.gif_available && d->species == SPECIES_GIF);
	m.species_idx = d->species < zbuddy_species_count() ? d->species : 0;
	m.base = ZBUDDY_SLEEP;
	m.active = ZBUDDY_SLEEP;
	LOG_INF("buddy: %s mode", m.ascii_mode ? "ASCII" : "GIF character");
}

static enum zbuddy_persona clock_mood(const struct clock_tm *t, uint32_t now_ms)
{
	bool weekend = (t->wday == 0 || t->wday == 6);
	bool friday = (t->wday == 5);
	int h = t->hour;

	if (h >= 1 && h < 7) {
		return ZBUDDY_SLEEP;
	}
	if (weekend) {
		return (now_ms / 8000 % 6 == 0) ? ZBUDDY_HEART : ZBUDDY_SLEEP;
	}
	if (h < 9) {
		return (now_ms / 6000 % 4 == 0) ? ZBUDDY_IDLE : ZBUDDY_SLEEP;
	}
	if (h == 12) {
		return (now_ms / 5000 % 3 == 0) ? ZBUDDY_HEART : ZBUDDY_IDLE;
	}
	if (friday && h >= 15) {
		return (now_ms / 4000 % 3 == 0) ? ZBUDDY_CELEBRATE : ZBUDDY_IDLE;
	}
	if (h >= 22 || h == 0) {
		return (now_ms / 7000 % 3 == 0) ? ZBUDDY_DIZZY : ZBUDDY_SLEEP;
	}
	return (now_ms / 10000 % 5 == 0) ? ZBUDDY_SLEEP : ZBUDDY_IDLE;
}

void buddy_tick(uint32_t now_ms)
{
	const struct zbuddy_snapshot *s = &proto.snap;
	enum zbuddy_persona before = m.active;
	static uint32_t last_passkey;
	uint32_t passkey;

	zbuddy_proto_poll(&proto, now_ms);
	if (zbuddy_stats_poll_level_up()) {
		one_shot(ZBUDDY_CELEBRATE, 3000, now_ms);
	}
	m.base = zbuddy_derive(s);
	/* after a wake, hold sleep for a while so the wake-up animation shows;
	 * urgent states override it */
	if (m.base == ZBUDDY_IDLE && (int32_t)(now_ms - m.wake_transition_until) < 0) {
		m.base = ZBUDDY_SLEEP;
	}
	if ((int32_t)(now_ms - m.one_shot_until) >= 0) {
		m.active = m.base;
	}

	/* prompt arrival: chirp, jump to the home screen */
	if (strcmp(s->prompt.id, last_prompt_id) != 0) {
		strncpy(last_prompt_id, s->prompt.id, sizeof(last_prompt_id) - 1);
		last_prompt_id[sizeof(last_prompt_id) - 1] = '\0';
		m.response_sent = false;
		m.in_prompt = s->prompt.id[0] != '\0';
		if (m.in_prompt) {
			m.prompt_arrived_ms = now_ms;
			buddy_wake(now_ms);
			beep(80);
			m.screen = SCREEN_HOME;
			close_overlays();
		}
	}

	/* the clock face when nothing is happening and the time is known */
	m.clocking = m.screen == SCREEN_HOME && m.overlay == OVERLAY_NONE && !m.in_prompt &&
		     s->sessions_running == 0 && s->sessions_waiting == 0 && clock_valid();
	if (m.clocking && (int32_t)(now_ms - m.one_shot_until) >= 0) {
		struct clock_tm t;

		if (clock_local(now_ms, &t)) {
			m.active = clock_mood(&t, now_ms);
		}
	}

	/* the pairing passkey wakes the screen */
	passkey = bridge_ble_passkey();
	if (passkey != 0 && last_passkey == 0) {
		buddy_wake(now_ms);
		beep(60);
	}
	last_passkey = passkey;

	/* LED: pulse on attention */
	hw_led(m.active == ZBUDDY_ATTENTION && persist_get()->prefs.led && (now_ms / 400) % 2);

	/* idle screen timeout (never during a prompt) */
	if (CONFIG_ZBUDDY_APP_SCREEN_OFF_S > 0 && !m.screen_off && !m.in_prompt &&
	    now_ms - m.last_interact_ms > (uint32_t)CONFIG_ZBUDDY_APP_SCREEN_OFF_S * 1000U) {
		m.screen_off = true;
		hw_screen(false);
	}
	if (forced_persona >= 0) {
		m.active = (enum zbuddy_persona)forced_persona;
	}
	if (m.active != before) {
		m.anim_gen++;
	}
}

void buddy_force_persona(int s)
{
	forced_persona = (s >= 0 && s < ZBUDDY_PERSONA_COUNT) ? s : -1;
}

void buddy_debug_show(enum buddy_screen screen, enum buddy_overlay overlay, uint8_t page)
{
	m.screen = screen;
	m.overlay = overlay;
	m.sel = 0;
	m.info_page = page % INFO_PAGES;
	m.pet_page = page % PET_PAGES;
}

const struct buddy_model *buddy_model(void)
{
	return &m;
}

struct zbuddy_proto *buddy_proto(void)
{
	return &proto;
}

const struct zbuddy_snapshot *buddy_snapshot(void)
{
	return &proto.snap;
}

const struct buddy_prefs *buddy_prefs(void)
{
	return &persist_get()->prefs;
}
```

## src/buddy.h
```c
/*
 * Copyright (c) 2026 Muhammad Waleed Badar
 * SPDX-License-Identifier: GPL-3.0-only
 *
 * The pet: what it feels (persona), what the screen shows (mode, pages,
 * menus) and what the inputs do. A port of the original device's loop,
 * without the drawing: ui.c renders this model.
 */
#ifndef ZBUDDY_APP_BUDDY_H
#define ZBUDDY_APP_BUDDY_H

#include "persist.h"
#include <zbuddy/proto.h>

enum buddy_screen {
	SCREEN_HOME,
	SCREEN_PET,
	SCREEN_INFO,
	SCREEN_COUNT,
};

enum buddy_overlay {
	OVERLAY_NONE,
	OVERLAY_MENU,
	OVERLAY_SETTINGS,
	OVERLAY_RESET,
};

#define INFO_PAGES 6
#define PET_PAGES 2
#define INFO_PG_BUTTONS 1
#define INFO_PG_CREDITS 5

struct buddy_model {
	enum zbuddy_persona base;
	enum zbuddy_persona active;
	uint32_t one_shot_until;
	enum buddy_screen screen;
	uint8_t info_page;
	uint8_t pet_page;
	enum buddy_overlay overlay;
	uint8_t sel; /* highlighted item of the open overlay (button navigation) */
	uint8_t reset_armed; /* 0xFF: nothing armed */
	uint32_t reset_armed_until;
	/* prompt */
	bool in_prompt; /* a prompt is pending and not yet answered */
	bool response_sent;
	uint32_t prompt_arrived_ms;
	/* sleep */
	bool napping;
	uint32_t nap_start_ms;
	bool screen_off;
	uint32_t last_interact_ms;
	uint32_t wake_transition_until;
	/* pet */
	bool ascii_mode;
	uint8_t species_idx;
	bool gif_available;
	bool clocking;
	uint32_t anim_gen; /* bumps when the pet must be redrawn at once */
};

void buddy_init(uint32_t now_ms);
/** Run the state machine; call every loop before the UI update. */
void buddy_tick(uint32_t now_ms);

const struct buddy_model *buddy_model(void);
struct zbuddy_proto *buddy_proto(void);
const struct zbuddy_snapshot *buddy_snapshot(void);

/* Inputs */
void buddy_tap_pet(uint32_t now_ms);        /* next screen, or approve during a prompt */
void buddy_long_press(uint32_t now_ms);     /* menu (in a menu: activate the highlighted item) */
void buddy_button_short(uint32_t now_ms);   /* the BOOT button: like a tap, in a menu: next item */
void buddy_next_page(uint32_t now_ms);      /* flip the PET / INFO page */
void buddy_pick(uint8_t idx, uint32_t now_ms); /* activate item idx of the open overlay */
void buddy_approve(uint32_t now_ms);
void buddy_deny(uint32_t now_ms);
void buddy_shake(uint32_t now_ms);
void buddy_wake(uint32_t now_ms);

/* Overlay contents for the UI */
const char *buddy_overlay_title(void);
uint8_t buddy_overlay_items(void);
/** Label of item @p idx, with its value ("sound   on"). */
void buddy_overlay_item(uint8_t idx, char *buf, size_t len, uint32_t now_ms);

/* Species, used by the protocol's "species" command too */
void buddy_set_species(uint8_t idx);
const char *buddy_species_name(void);

const struct buddy_prefs *buddy_prefs(void);

/* Debug hooks (native_sim screenshots): force a persona (-1 = off), open a screen */
void buddy_force_persona(int s);
void buddy_debug_show(enum buddy_screen screen, enum buddy_overlay overlay, uint8_t page);

#endif
```

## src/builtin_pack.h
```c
/*
 * Copyright (c) 2026 Muhammad Waleed Badar
 * SPDX-License-Identifier: GPL-3.0-only
 *
 * The character pack built into the firmware (generated by tools/mkpack.py):
 * what the pet looks like before any pack is pushed from the desktop.
 */
#ifndef ZBUDDY_APP_BUILTIN_PACK_H
#define ZBUDDY_APP_BUILTIN_PACK_H

#include <stddef.h>
#include <stdint.h>

struct builtin_file {
	const char *name;
	const uint8_t *data;
	size_t len;
};

extern const struct builtin_file builtin_pack_files[];
extern const size_t builtin_pack_count;
extern const char *const builtin_pack_name;

#endif
```

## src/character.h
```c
/*
 * Copyright (c) 2026 Muhammad Waleed Badar
 * SPDX-License-Identifier: GPL-3.0-only
 *
 * The installed character pack: GIFs (or text frames) per state, played
 * with LVGL's GIF widget from memory.
 */
#ifndef ZBUDDY_APP_CHARACTER_H
#define ZBUDDY_APP_CHARACTER_H

#include <zbuddy/character.h>
#include <lvgl.h>

/** Create the widgets (hidden until a pack is loaded). */
void character_create(lv_obj_t *parent);
/** Load the pack @p name, or the first installed one when NULL. */
bool character_init(const char *name);
bool character_loaded(void);
const char *character_name(void);
/** True while the built-in pack (not a pushed one) is loaded. */
bool character_builtin(void);
const struct zbuddy_palette *character_palette(void);
void character_close(void);
void character_set_state(enum zbuddy_persona s, uint32_t now_ms);
void character_tick(uint32_t now_ms);
/** Show or hide the widgets. */
void character_show(bool visible);

#endif
```
